# SAM9X75D5M device description
Architecture: ARM926EJ-S; Family: SAM9; Series: SAM9X7
Registers are 32-bit, read-write, reset 0x0 unless marked. A register's access mark holds for its fields unless they carry their own. Offsets are from the block's base; [hi:lo] are bit positions; 'fields as' and 'values as' point back to an identical list.

## SFR — Special Function Registers
Instances: SFR 0xF8050000
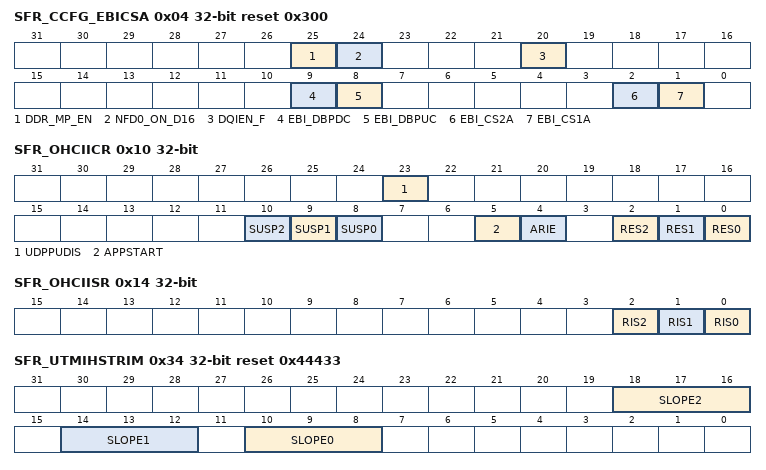
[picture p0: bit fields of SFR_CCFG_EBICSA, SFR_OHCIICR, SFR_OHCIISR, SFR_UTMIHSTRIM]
0x04 SFR_CCFG_EBICSA reset 0x300 — EBI Chip Select Register
  [25] DDR_MP_EN — DDR Multi-port Enable
    0=DDR Multi-port is disabled (default); 1=DDR Multi-port is enabled, performance is increased
  [24] NFD0_ON_D16 — NAND Flash Databus Selection
    0=NAND Flash I/Os are connected to D0-D7 (default); 1=NAND Flash I/Os are connected to D16-D23
  [20] DQIEN_F — Force Analog Input Comparator Configuration
    0=No effect; 1=Enables the input comparator in the VDDIOM I/O data lines. Must be set to one in an initialization phase whenever an MPDDRC external component (DDR2 or LPDDR) and an SMC external component (e.g., NAND Flash) are multiplexed on the D0-D15 bus.
  [9] EBI_DBPDC — EBI Data Bus Pulldown Configuration
    0=EBI D0-D15 Data Bus bits are not internally pulled down; 1=EBI D0-D15 Data Bus bits are internally pulled down to the ground
  [8] EBI_DBPUC — EBI Data Bus Pullup Configuration
    0=EBI D0-D15 Data Bus bits are internally pulled up to the VDDIOM power supply; 1=EBI D0-D15 Data Bus bits are not internally pulled up
  [2] EBI_CS2A — EBI Chip Select 2 Assignment
    0=EBI Chip Select 2 is only assigned to the SMC and EBI_NCS2 behaves as defined by the SMC; 1=EBI Chip Select 2 is assigned to the SMC and the NAND Flash logic is activated
  [1] EBI_CS1A — EBI Chip Select 1 Assignment
    0=EBI Chip Select 1 is assigned to the Static Memory Controller (SMC); 1=EBI Chip Select 1 is assigned to the AHB Multiport DDR-SDRAM Controller (MPDDRC)
0x10 SFR_OHCIICR — OHCI Interrupt Configuration Register
  [23] UDPPUDIS — Reserved
    0=Must write 0
  [10] SUSP2 — USB PORTx
    0=Does not suspend USB PORTx; 1=Forces PORTx suspend
  [9] SUSP1 — USB PORTx
    0=Does not suspend USB PORTx; 1=Forces PORTx suspend
  [8] SUSP0 — USB PORTx
    0=Does not suspend USB PORTx; 1=Forces PORTx suspend
  [5] APPSTART — Reserved
    0=Must write 0
  [4] ARIE — OHCI Asynchronous Resume Interrupt Enable
    0=Disables interrupt; 1=Enables interrupt
  [2] RES2 — USB PORTx Reset
    0=No effect (USB PORTx reset released, default value); 1=Resets USB PORTx
  [1] RES1 — USB PORTx Reset
    values as RES2
  [0] RES0 — USB PORTx Reset
    values as RES2
0x14 SFR_OHCIISR ro — OHCI Interrupt Status Register
  [all] fields
    0=OHCI port resume is not detected; 1=OHCI port resume is detected
  [2] RIS2 — OHCI Resume Interrupt Status Port 2
  [1] RIS1 — OHCI Resume Interrupt Status Port 1
  [0] RIS0 — OHCI Resume Interrupt Status Port 0
0x34 SFR_UTMIHSTRIM reset 0x44433 — UTMI High-Speed Trimming Register
  [18:16] SLOPE2 — UTMI HS PORTx Transceiver Slope Trimming
  [14:12] SLOPE1 — UTMI HS PORTx Transceiver Slope Trimming
  [10:8] SLOPE0 — UTMI HS PORTx Transceiver Slope Trimming
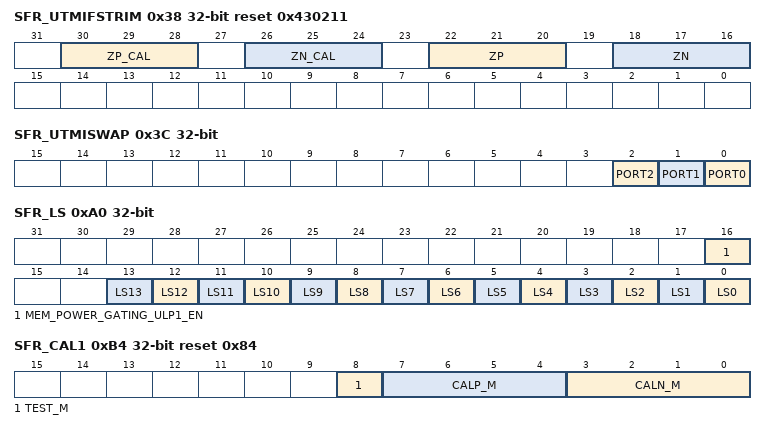
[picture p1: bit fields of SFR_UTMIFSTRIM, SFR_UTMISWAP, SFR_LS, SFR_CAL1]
0x38 SFR_UTMIFSTRIM reset 0x430211 — UTMI Full-Speed Trimming Register
  [30:28] ZP_CAL — FS Transceiver PMOS Impedance Calibration
  [26:24] ZN_CAL — FS Transceiver NMOS Impedance Calibration
  [22:20] ZP — FS Transceiver PMOS Impedance Trimming
  [18:16] ZN — FS Transceiver NMOS Impedance Trimming
0x3C SFR_UTMISWAP — UTMI DP/DM Pin Swapping Register
  [all] fields
    0=NORMAL (DP/DM normal pinout); 1=SWAPPED (DP/DM swapped pinout)
  [2] PORT2 — Port 2 DP/DM Pin Swapping
  [1] PORT1 — Port 1 DP/DM Pin Swapping
  [0] PORT0 — Port 0 DP/DM Pin Swapping
0xA0 SFR_LS — Light Sleep Register
  [16] MEM_POWER_GATING_ULP1_EN — Light Sleep Value for ULP1 Power-Gated Memories
    0=Light Sleep mode is not activated by the MEM_POWER_GATING_ULP1 output signal from the PMC; 1=Light Sleep mode is activated when the MEM_POWER_GATING_ULP1 output signal from the PMC is activated
  [13] LS13 — Light Sleep Value (GMAC)
  [12] LS12 — Light Sleep Value (DSI)
  [11] LS11 — Light Sleep Value (ISC)
  [10] LS10 — Light Sleep Value (CSI2DC)
  [9] LS9 — Light Sleep Value (ARM926)
  [8] LS8 — Light Sleep Value (ROM + OTPC)
  [7] LS7 — Light Sleep Value (FLEXRAM1 (OTPC))
  [6] LS6 — Light Sleep Value (FLEXRAM0)
  [5] LS5 — Light Sleep Value (UHPHS)
  [4] LS4 — Light Sleep Value (XDMAC)
  [3] LS3 — Light Sleep Value (UDPHS)
  [2] LS2 — Light Sleep Value (SDMMC)
  [1] LS1 — Light Sleep Value (XLCDC)
  [0] LS0 — Light Sleep Value (GFX2D)
0xB4 SFR_CAL1 reset 0x84 — I/O Calibration 1 Register
  [8] TEST_M — Enable Calibration of Low/High Level Output Impedance of Pads with VDDIOM Supply
  [7:4] CALP_M — Calibration of High Level Output Impedance of Pads with VDDIOM Supply
  [3:0] CALN_M — Calibration of Low Level Output Impedance of Pads with VDDIOM Supply
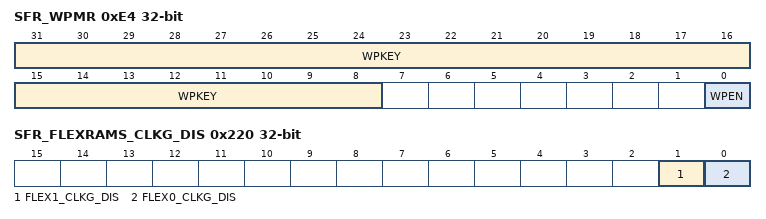
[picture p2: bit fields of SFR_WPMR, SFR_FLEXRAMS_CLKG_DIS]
0xE4 SFR_WPMR — Write Protection Mode Register
  [31:8] WPKEY — Write Protection Key
    0x534652=PASSWD (Writing any other value in this field aborts the write operation of the WPEN bit. Always reads as 0.)
  [0] WPEN — Write Protection Enable
    0=Disables write protection if WPKEY corresponds to 0x534652 ("SFR" in ASCII); 1=Enables write protection if WPKEY corresponds to 0x534652 ("SFR" in ASCII)
0x20C SFR_PUFRUCR0 — Quidikkey Restrict User Context 0 Register
  [31:0] RESTRICT_USER_CONTEXT_0 — Value Connected to qk_restrict_user_context_0 input for QK
0x210 SFR_PUFRUCR1 — Quidikkey Restrict User Context 1 Register
  [31:0] RESTRICT_USER_CONTEXT_1 — Value Connected to qk_restrict_user_context_1 input for QK
0x214 SFR_PUFWORUCR0 — Quidikkey Restrict User Context 0 Write Ones Register
  [31:0] RESTRICT_USER_CONTEXT_0_WO — Value Connected to qk_restrict_user_context_0 input for QK
0x218 SFR_PUFWORUCR1 — Quidikkey Restrict User Context 1 Write Ones Register
  [31:0] RESTRICT_USER_CONTEXT_1_WO — Value Connected to qk_restrict_user_context_1 input for QK
0x220 SFR_FLEXRAMS_CLKG_DIS — FLEXRAMS Clock Gating Disable Register
  [1] FLEX1_CLKG_DIS — Clock Gating Disable for FLEXRAM1
    0=Clock Gating is enabled; 1=Clock Gating is disabled
  [0] FLEX0_CLKG_DIS — Clock Gating Disable for FLEXRAM0
    0=Clock Gating is enabled; 1=Clock Gating is disabled
0x240 SFR_ISS_CFG — ISS Configuration Register
  [0] MODE — DSI/CSI Selection
    0=CSI (CSI mode); 1=DSI (DSI mode)
0x250 SFR_TSU_CFG reset 0x43 — TSU Configuration Register
  [7:0] WIDTH — Number of TSU Cycles to Increase GTSUCOMP Width
0x260 SFR_REMAP_MP_DDR — Remap Multiport DDR Register
